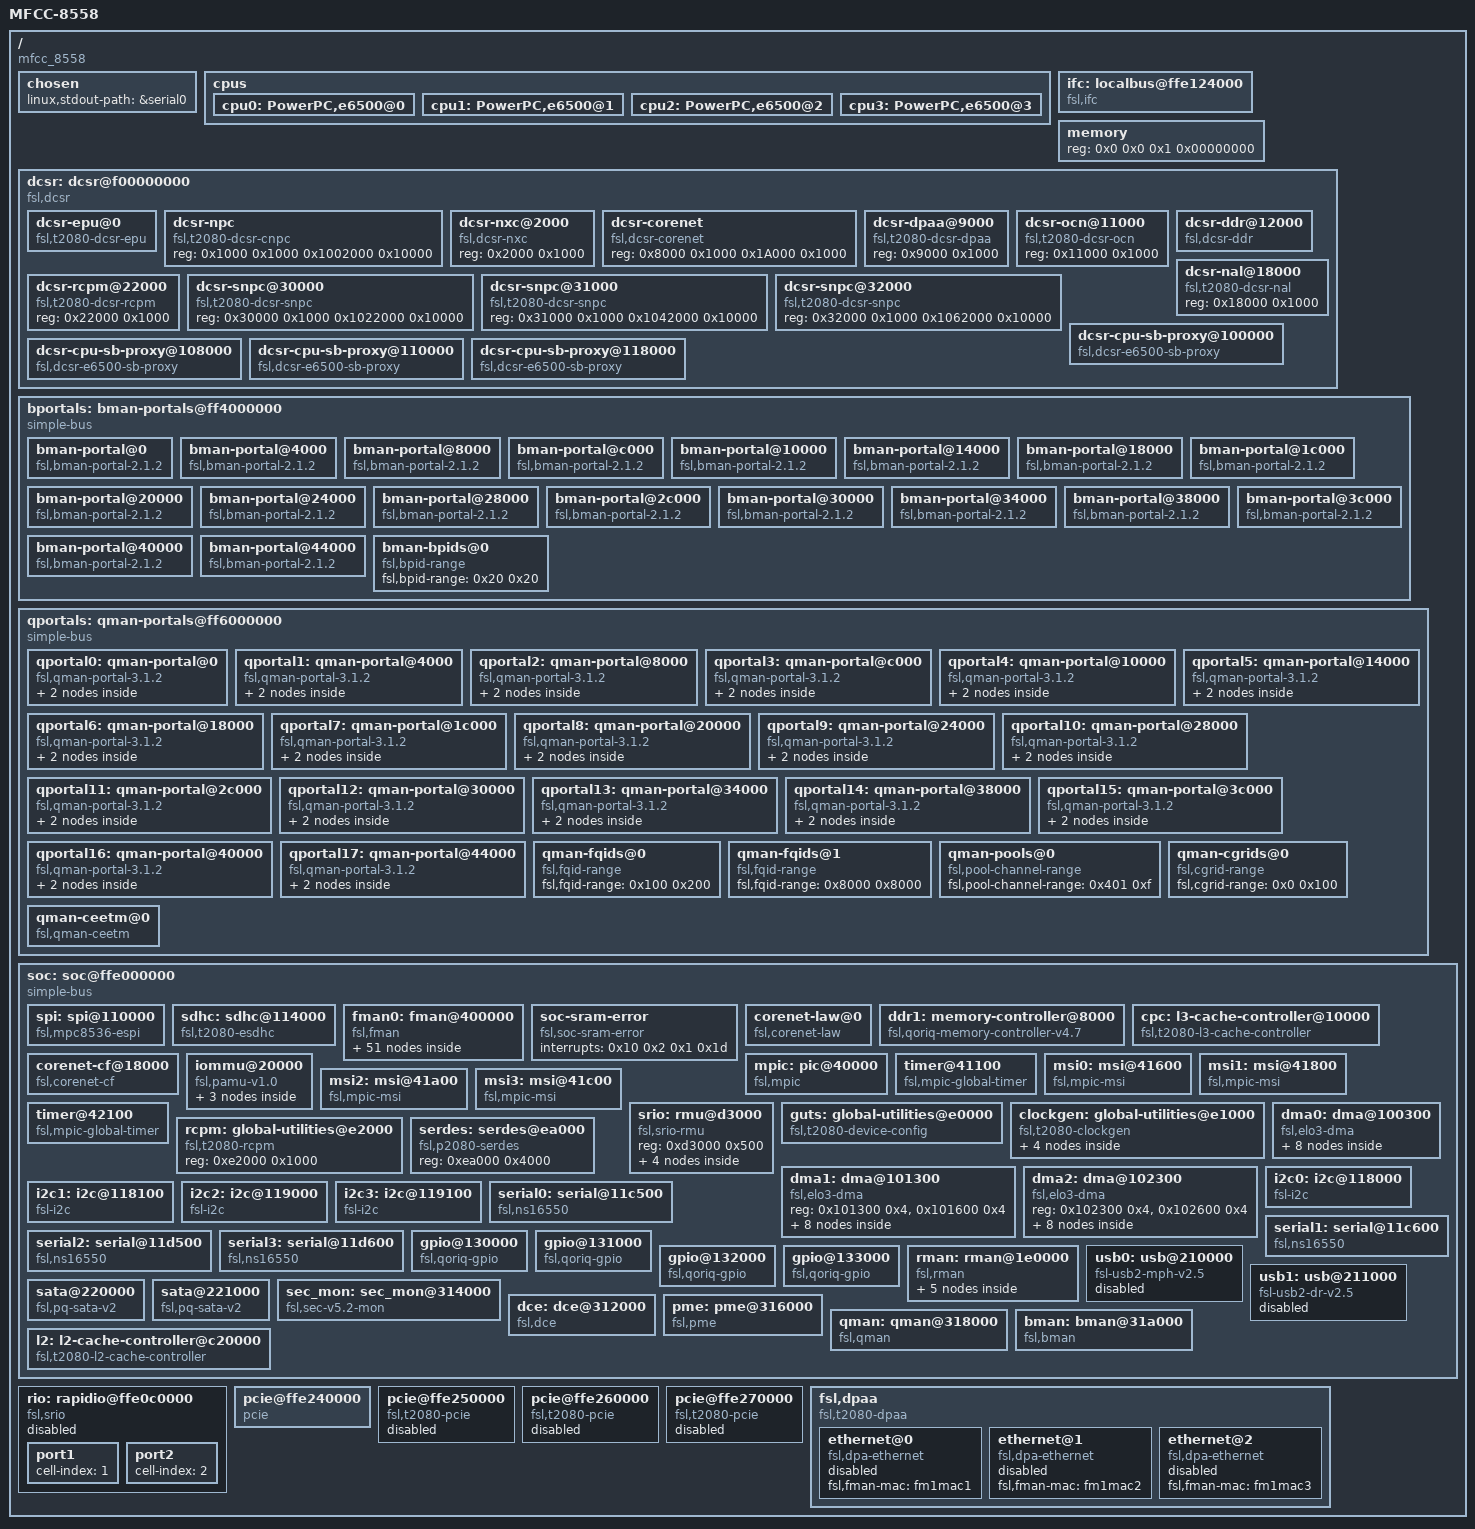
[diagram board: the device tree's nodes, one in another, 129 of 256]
/*
    Interrupts:
        <cell 1>:   interrupt number
        <cell 2>:   level-sense
                    - 0:    low-to-high edge triggered
                    - 1:    active low level-sense
                    - 2:    active high level-sense
                    - 3:    high-to-low edge triggered
        <cell 3>:   interrupt type
                    - 0:    external or normal SOC device interrupt
                    - 1:    error interrupt
        <cell 4>:   type specific cell
                    a) for error interrupts
                    - bit number of the error interrupt in error interrupt
                      summary register

*/

/* Reserve bootpage */
/memreserve/	0x00000000fffff000 0x0000000000001000;
/* Reserver memory for bman and qman */
/memreserve/	0x000000007c000000 0x0000000001000000;
/memreserve/	0x000000007e000000 0x0000000001000000;
/memreserve/	0x000000007d000000 0x0000000001000000;

/ {
	#address-cells = <2>;
	#size-cells = <2>;
	interrupt-parent = <&mpic>;
	model = "MFCC-8558";
	compatible = "mfcc_8558";

	chosen {
		linux,stdout-path = &serial0;
	};

	cpus {
		#address-cells = <1>;
		#size-cells = <0>;

		/*
		 * Temporarily add next-level-cache info in each cpu node so
		 * that uboot can do L2 cache fixup. This can be removed once
		 * u-boot can create cpu node with cache info.
		 */
		cpu0: PowerPC,e6500@0 {
			device_type = "cpu";
			reg = <0 1>;
			clocks = <&mux0>;
			next-level-cache = <&l2>;

			i-cache-sets = <0x40>;
			i-cache-size = <0x8000>;
			i-cache-block-size = <0x40>;
			cache-stash-id = <0x20>;
			d-cache-sets = <0x40>;
			d-cache-size = <0x8000>;
			d-cache-block-size = <0x40>;
		};
		cpu1: PowerPC,e6500@1 {
			device_type = "cpu";
			reg = <2 3>;
			clocks = <&mux0>;
			next-level-cache = <&l2>;

			i-cache-sets = <0x40>;
			i-cache-size = <0x8000>;
			i-cache-block-size = <0x40>;
			cache-stash-id = <0x24>;
			d-cache-sets = <0x40>;
			d-cache-size = <0x8000>;
			d-cache-block-size = <0x40>;
		};
		cpu2: PowerPC,e6500@2 {
			device_type = "cpu";
			reg = <4 5>;
			clocks = <&mux0>;
			next-level-cache = <&l2>;

			i-cache-sets = <0x40>;
			i-cache-size = <0x8000>;
			i-cache-block-size = <0x40>;
			cache-stash-id = <0x28>;
			d-cache-sets = <0x40>;
			d-cache-size = <0x8000>;
			d-cache-block-size = <0x40>;
		};
		cpu3: PowerPC,e6500@3 {
			device_type = "cpu";
			reg = <6 7>;
			clocks = <&mux0>;
			next-level-cache = <&l2>;

			i-cache-sets = <0x40>;
			i-cache-size = <0x8000>;
			i-cache-block-size = <0x40>;
			cache-stash-id = <0x2c>;
			d-cache-sets = <0x40>;
			d-cache-size = <0x8000>;
			d-cache-block-size = <0x40>;
		};
	};

	ifc: localbus@ffe124000 {
		compatible = "fsl,ifc", "simple-bus";

		reg = <15 0xfe124000 0 0x2000>;

		interrupts = <25 2 0 0>;
		#address-cells = <2>;
		#size-cells = <1>;
	};

	memory {
		device_type = "memory";
		reg = <0x0 0x0 0x1 0x00000000>;
	};

	dcsr: dcsr@f00000000 {
		ranges = <0x0 0xf 0x0 0x1072000>;
		#address-cells = <1>;
		#size-cells = <1>;
		compatible = "fsl,dcsr", "simple-bus";

		dcsr-epu@0 {
			compatible = "fsl,t2080-dcsr-epu", "fsl,dcsr-epu";
			interrupts = <52 2 0 0
			              84 2 0 0
			              85 2 0 0
			              94 2 0 0
			              95 2 0 0>;
			reg = <0x0 0x1000>;
		};
		dcsr-npc {
			compatible = "fsl,t2080-dcsr-cnpc", "fsl,dcsr-cnpc";
			reg = <0x1000 0x1000 0x1002000 0x10000>;
		};
		dcsr-nxc@2000 {
			compatible = "fsl,dcsr-nxc";
			reg = <0x2000 0x1000>;
		};
		dcsr-corenet {
			compatible = "fsl,dcsr-corenet";
			reg = <0x8000 0x1000 0x1A000 0x1000>;
		};
		dcsr-dpaa@9000 {
			compatible = "fsl,t2080-dcsr-dpaa", "fsl,dcsr-dpaa";
			reg = <0x9000 0x1000>;
		};
		dcsr-ocn@11000 {
			compatible = "fsl,t2080-dcsr-ocn", "fsl,dcsr-ocn";
			reg = <0x11000 0x1000>;
		};
		dcsr-ddr@12000 {
			compatible = "fsl,dcsr-ddr";
			dev-handle = <&ddr1>;
			reg = <0x12000 0x1000>;
		};
		dcsr-nal@18000 {
			compatible = "fsl,t2080-dcsr-nal", "fsl,dcsr-nal";
			reg = <0x18000 0x1000>;
		};
		dcsr-rcpm@22000 {
			compatible = "fsl,t2080-dcsr-rcpm", "fsl,dcsr-rcpm";
			reg = <0x22000 0x1000>;
		};
		dcsr-snpc@30000 {
			compatible = "fsl,t2080-dcsr-snpc", "fsl,dcsr-snpc";
			reg = <0x30000 0x1000 0x1022000 0x10000>;
		};
		dcsr-snpc@31000 {
			compatible = "fsl,t2080-dcsr-snpc", "fsl,dcsr-snpc";
			reg = <0x31000 0x1000 0x1042000 0x10000>;
		};
		dcsr-snpc@32000 {
			compatible = "fsl,t2080-dcsr-snpc", "fsl,dcsr-snpc";
			reg = <0x32000 0x1000 0x1062000 0x10000>;
		};
		dcsr-cpu-sb-proxy@100000 {
			compatible = "fsl,dcsr-e6500-sb-proxy", "fsl,dcsr-cpu-sb-proxy";
			cpu-handle = <&cpu0>;
			reg = <0x100000 0x1000 0x101000 0x1000>;
		};
		dcsr-cpu-sb-proxy@108000 {
			compatible = "fsl,dcsr-e6500-sb-proxy", "fsl,dcsr-cpu-sb-proxy";
			cpu-handle = <&cpu1>;
			reg = <0x108000 0x1000 0x109000 0x1000>;
		};
		dcsr-cpu-sb-proxy@110000 {
			compatible = "fsl,dcsr-e6500-sb-proxy", "fsl,dcsr-cpu-sb-proxy";
			cpu-handle = <&cpu2>;
			reg = <0x110000 0x1000 0x111000 0x1000>;
		};
		dcsr-cpu-sb-proxy@118000 {
			compatible = "fsl,dcsr-e6500-sb-proxy", "fsl,dcsr-cpu-sb-proxy";
			cpu-handle = <&cpu3>;
			reg = <0x118000 0x1000 0x119000 0x1000>;
		};
	};

	bportals: bman-portals@ff4000000 {
		ranges = <0x0 0xf 0xf4000000 0x2000000>;
		#address-cells = <0x1>;
		#size-cells = <0x1>;
		compatible = "simple-bus";

		bman-portal@0 {
			cell-index = <0x0>;
			compatible = "fsl,bman-portal-2.1.2", "fsl,bman-portal";
			reg = <0x0 0x4000 0x1000000 0x1000>;
			interrupts = <0x69 0x2 0x0 0x0>;
		};

		bman-portal@4000 {
			cell-index = <0x1>;
			compatible = "fsl,bman-portal-2.1.2", "fsl,bman-portal";
			reg = <0x4000 0x4000 0x1001000 0x1000>;
			interrupts = <0x6b 0x2 0x0 0x0>;
		};

		bman-portal@8000 {
			cell-index = <0x2>;
			compatible = "fsl,bman-portal-2.1.2", "fsl,bman-portal";
			reg = <0x8000 0x4000 0x1002000 0x1000>;
			interrupts = <0x6d 0x2 0x0 0x0>;
		};

		bman-portal@c000 {
			cell-index = <0x3>;
			compatible = "fsl,bman-portal-2.1.2", "fsl,bman-portal";
			reg = <0xc000 0x4000 0x1003000 0x1000>;
			interrupts = <0x6f 0x2 0x0 0x0>;
		};

		bman-portal@10000 {
			cell-index = <0x4>;
			compatible = "fsl,bman-portal-2.1.2", "fsl,bman-portal";
			reg = <0x10000 0x4000 0x1004000 0x1000>;
			interrupts = <0x71 0x2 0x0 0x0>;
		};

		bman-portal@14000 {
			cell-index = <0x5>;
			compatible = "fsl,bman-portal-2.1.2", "fsl,bman-portal";
			reg = <0x14000 0x4000 0x1005000 0x1000>;
			interrupts = <0x73 0x2 0x0 0x0>;
		};

		bman-portal@18000 {
			cell-index = <0x6>;
			compatible = "fsl,bman-portal-2.1.2", "fsl,bman-portal";
			reg = <0x18000 0x4000 0x1006000 0x1000>;
			interrupts = <0x75 0x2 0x0 0x0>;
		};

		bman-portal@1c000 {
			cell-index = <0x7>;
			compatible = "fsl,bman-portal-2.1.2", "fsl,bman-portal";
			reg = <0x1c000 0x4000 0x1007000 0x1000>;
			interrupts = <0x77 0x2 0x0 0x0>;
		};

		bman-portal@20000 {
			cell-index = <0x8>;
			compatible = "fsl,bman-portal-2.1.2", "fsl,bman-portal";
			reg = <0x20000 0x4000 0x1008000 0x1000>;
			interrupts = <0x79 0x2 0x0 0x0>;
		};

		bman-portal@24000 {
			cell-index = <0x9>;
			compatible = "fsl,bman-portal-2.1.2", "fsl,bman-portal";
			reg = <0x24000 0x4000 0x1009000 0x1000>;
			interrupts = <0x7b 0x2 0x0 0x0>;
		};

		bman-portal@28000 {
			cell-index = <0xa>;
			compatible = "fsl,bman-portal-2.1.2", "fsl,bman-portal";
			reg = <0x28000 0x4000 0x100a000 0x1000>;
			interrupts = <0x7d 0x2 0x0 0x0>;
		};

		bman-portal@2c000 {
			cell-index = <0xb>;
			compatible = "fsl,bman-portal-2.1.2", "fsl,bman-portal";
			reg = <0x2c000 0x4000 0x100b000 0x1000>;
			interrupts = <0x7f 0x2 0x0 0x0>;
		};

		bman-portal@30000 {
			cell-index = <0xc>;
			compatible = "fsl,bman-portal-2.1.2", "fsl,bman-portal";
			reg = <0x30000 0x4000 0x100c000 0x1000>;
			interrupts = <0x81 0x2 0x0 0x0>;
		};

		bman-portal@34000 {
			cell-index = <0xd>;
			compatible = "fsl,bman-portal-2.1.2", "fsl,bman-portal";
			reg = <0x34000 0x4000 0x100d000 0x1000>;
			interrupts = <0x83 0x2 0x0 0x0>;
		};

		bman-portal@38000 {
			cell-index = <0xe>;
			compatible = "fsl,bman-portal-2.1.2", "fsl,bman-portal";
			reg = <0x38000 0x4000 0x100e000 0x1000>;
			interrupts = <0x85 0x2 0x0 0x0>;
		};

		bman-portal@3c000 {
			cell-index = <0xf>;
			compatible = "fsl,bman-portal-2.1.2", "fsl,bman-portal";
			reg = <0x3c000 0x4000 0x100f000 0x1000>;
			interrupts = <0x87 0x2 0x0 0x0>;
		};

		bman-portal@40000 {
			cell-index = <0x10>;
			compatible = "fsl,bman-portal-2.1.2", "fsl,bman-portal";
			reg = <0x40000 0x4000 0x1010000 0x1000>;
			interrupts = <0x89 0x2 0x0 0x0>;
		};

		bman-portal@44000 {
			cell-index = <0x11>;
			compatible = "fsl,bman-portal-2.1.2", "fsl,bman-portal";
			reg = <0x44000 0x4000 0x1011000 0x1000>;
			interrupts = <0x8b 0x2 0x0 0x0>;
		};

		bman-bpids@0 {
			compatible = "fsl,bpid-range";
			fsl,bpid-range = <0x20 0x20>;
		};
	};

	qportals: qman-portals@ff6000000 {
		ranges = <0x0 0xf 0xf6000000 0x2000000>;
		#address-cells = <0x1>;
		#size-cells = <0x1>;
		compatible = "simple-bus";

		qportal0: qman-portal@0 {
			cell-index = <0x0>;
			compatible = "fsl,qman-portal-3.1.2", "fsl,qman-portal";
			reg = <0x0 0x4000 0x1000000 0x1000>;
			interrupts = <0x68 0x2 0x0 0x0>;
			fsl,qman-channel-id = <0x0>;

			fman@0 {
				dev-handle = <&fman0>;
			};

			pme@0 {
				dev-handle = <&pme>;
			};
		};

		qportal1: qman-portal@4000 {
			cell-index = <0x1>;
			compatible = "fsl,qman-portal-3.1.2", "fsl,qman-portal";
			reg = <0x4000 0x4000 0x1001000 0x1000>;
			interrupts = <0x6a 0x2 0x0 0x0>;
			fsl,qman-channel-id = <0x1>;

			fman@0 {
				dev-handle = <&fman0>;
			};

			pme@0 {
				dev-handle = <&pme>;
			};
		};

		qportal2: qman-portal@8000 {
			cell-index = <0x2>;
			compatible = "fsl,qman-portal-3.1.2", "fsl,qman-portal";
			reg = <0x8000 0x4000 0x1002000 0x1000>;
			interrupts = <0x6c 0x2 0x0 0x0>;
			fsl,qman-channel-id = <0x2>;

			fman@0 {
				dev-handle = <&fman0>;
			};

			pme@0 {
				dev-handle = <&pme>;
			};
		};

		qportal3: qman-portal@c000 {
			cell-index = <0x3>;
			compatible = "fsl,qman-portal-3.1.2", "fsl,qman-portal";
			reg = <0xc000 0x4000 0x1003000 0x1000>;
			interrupts = <0x6e 0x2 0x0 0x0>;
			fsl,qman-channel-id = <0x3>;

			fman@0 {
				dev-handle = <&fman0>;
			};

			pme@0 {
				dev-handle = <&pme>;
			};
		};

		qportal4: qman-portal@10000 {
			cell-index = <0x4>;
			compatible = "fsl,qman-portal-3.1.2", "fsl,qman-portal";
			reg = <0x10000 0x4000 0x1004000 0x1000>;
			interrupts = <0x70 0x2 0x0 0x0>;
			fsl,qman-channel-id = <0x4>;

			fman@0 {
				dev-handle = <&fman0>;
			};

			pme@0 {
				dev-handle = <&pme>;
			};
		};

		qportal5: qman-portal@14000 {
			cell-index = <0x5>;
			compatible = "fsl,qman-portal-3.1.2", "fsl,qman-portal";
			reg = <0x14000 0x4000 0x1005000 0x1000>;
			interrupts = <0x72 0x2 0x0 0x0>;
			fsl,qman-channel-id = <0x5>;

			fman@0 {
				dev-handle = <&fman0>;
			};

			pme@0 {
				dev-handle = <&pme>;
			};
		};

		qportal6: qman-portal@18000 {
			cell-index = <0x6>;
			compatible = "fsl,qman-portal-3.1.2", "fsl,qman-portal";
			reg = <0x18000 0x4000 0x1006000 0x1000>;
			interrupts = <0x74 0x2 0x0 0x0>;
			fsl,qman-channel-id = <0x6>;

			fman@0 {
				dev-handle = <&fman0>;
			};

			pme@0 {
				dev-handle = <&pme>;
			};
		};

		qportal7: qman-portal@1c000 {
			cell-index = <0x7>;
			compatible = "fsl,qman-portal-3.1.2", "fsl,qman-portal";
			reg = <0x1c000 0x4000 0x1007000 0x1000>;
			interrupts = <0x76 0x2 0x0 0x0>;
			fsl,qman-channel-id = <0x7>;

			fman@0 {
				dev-handle = <&fman0>;
			};

			pme@0 {
				dev-handle = <&pme>;
			};
		};

		qportal8: qman-portal@20000 {
			cell-index = <0x8>;
			compatible = "fsl,qman-portal-3.1.2", "fsl,qman-portal";
			reg = <0x20000 0x4000 0x1008000 0x1000>;
			interrupts = <0x78 0x2 0x0 0x0>;
			fsl,qman-channel-id = <0x8>;

			fman@0 {
				dev-handle = <&fman0>;
			};

			pme@0 {
				dev-handle = <&pme>;
			};
		};

		qportal9: qman-portal@24000 {
			cell-index = <0x9>;
			compatible = "fsl,qman-portal-3.1.2", "fsl,qman-portal";
			reg = <0x24000 0x4000 0x1009000 0x1000>;
			interrupts = <0x7a 0x2 0x0 0x0>;
			fsl,qman-channel-id = <0x9>;

			fman@0 {
				dev-handle = <&fman0>;
			};

			pme@0 {
				dev-handle = <&pme>;
			};
		};

		qportal10: qman-portal@28000 {
			cell-index = <0xa>;
			compatible = "fsl,qman-portal-3.1.2", "fsl,qman-portal";
			reg = <0x28000 0x4000 0x100a000 0x1000>;
			interrupts = <0x7c 0x2 0x0 0x0>;
			fsl,qman-channel-id = <0xa>;

			fman@0 {
				dev-handle = <&fman0>;
			};

			pme@0 {
				dev-handle = <&pme>;
			};
		};

		qportal11: qman-portal@2c000 {
			cell-index = <0xb>;
			compatible = "fsl,qman-portal-3.1.2", "fsl,qman-portal";
			reg = <0x2c000 0x4000 0x100b000 0x1000>;
			interrupts = <0x7e 0x2 0x0 0x0>;
			fsl,qman-channel-id = <0xb>;

			fman@0 {
				dev-handle = <&fman0>;
			};

			pme@0 {
				dev-handle = <&pme>;
			};
		};

		qportal12: qman-portal@30000 {
			cell-index = <0xc>;
			compatible = "fsl,qman-portal-3.1.2", "fsl,qman-portal";
			reg = <0x30000 0x4000 0x100c000 0x1000>;
			interrupts = <0x80 0x2 0x0 0x0>;
			fsl,qman-channel-id = <0xc>;

			fman@0 {
				dev-handle = <&fman0>;
			};

			pme@0 {
				dev-handle = <&pme>;
			};
		};

		qportal13: qman-portal@34000 {
			cell-index = <0xd>;
			compatible = "fsl,qman-portal-3.1.2", "fsl,qman-portal";
			reg = <0x34000 0x4000 0x100d000 0x1000>;
			interrupts = <0x82 0x2 0x0 0x0>;
			fsl,qman-channel-id = <0xd>;

			fman@0 {
				dev-handle = <&fman0>;
			};

			pme@0 {
				dev-handle = <&pme>;
			};
		};

		qportal14: qman-portal@38000 {
			cell-index = <0xe>;
			compatible = "fsl,qman-portal-3.1.2", "fsl,qman-portal";
			reg = <0x38000 0x4000 0x100e000 0x1000>;
			interrupts = <0x84 0x2 0x0 0x0>;
			fsl,qman-channel-id = <0xe>;

			fman@0 {
				dev-handle = <&fman0>;
			};

			pme@0 {
				dev-handle = <&pme>;
			};
		};

		qportal15: qman-portal@3c000 {
			cell-index = <0xf>;
			compatible = "fsl,qman-portal-3.1.2", "fsl,qman-portal";
			reg = <0x3c000 0x4000 0x100f000 0x1000>;
			interrupts = <0x86 0x2 0x0 0x0>;
			fsl,qman-channel-id = <0xf>;

			fman@0 {
				dev-handle = <&fman0>;
			};

			pme@0 {
				dev-handle = <&pme>;
			};
		};

		qportal16: qman-portal@40000 {
			cell-index = <0x10>;
			compatible = "fsl,qman-portal-3.1.2", "fsl,qman-portal";
			reg = <0x40000 0x4000 0x1010000 0x1000>;
			interrupts = <0x88 0x2 0x0 0x0>;
			fsl,qman-channel-id = <0x10>;

			fman@0 {
				dev-handle = <&fman0>;
			};

			pme@0 {
				dev-handle = <&pme>;
			};
		};

		qportal17: qman-portal@44000 {
			cell-index = <0x11>;
			compatible = "fsl,qman-portal-3.1.2", "fsl,qman-portal";
			reg = <0x44000 0x4000 0x1011000 0x1000>;
			interrupts = <0x8a 0x2 0x0 0x0>;
			fsl,qman-channel-id = <0x11>;

			fman@0 {
				dev-handle = <&fman0>;
			};

			pme@0 {
				dev-handle = <&pme>;
			};
		};

		qman-fqids@0 {
			compatible = "fsl,fqid-range";
			fsl,fqid-range = <0x100 0x200>;
		};

		qman-fqids@1 {
			compatible = "fsl,fqid-range";
			fsl,fqid-range = <0x8000 0x8000>;
		};

		qman-pools@0 {
			compatible = "fsl,pool-channel-range";
			fsl,pool-channel-range = <0x401 0xf>;
		};

		qman-cgrids@0 {
			compatible = "fsl,cgrid-range";
			fsl,cgrid-range = <0x0 0x100>;
		};

		qman-ceetm@0 {
			compatible = "fsl,qman-ceetm";
			fsl,ceetm-lfqid-range = <0xf00000 0x1000>;
			fsl,ceetm-sp-range = <0x0 0xc>;
			fsl,ceetm-lni-range = <0x0 0x8>;
			fsl,ceetm-channel-range = <0x0 0x20>;
		};
	};

	soc: soc@ffe000000 {
		bus-frequency = <600000000>;
		ranges = <0x0 0xf 0xfe000000 0x1000000>;
		reg = <0xf 0xfe000000 0x0 0x1000>;
		#address-cells = <0x1>;
		#size-cells = <0x1>;
		device_type = "soc";
		compatible = "simple-bus";

		spi: spi@110000 {
			#address-cells = <0x1>;
			#size-cells = <0x0>;
			compatible = "fsl,mpc8536-espi";
			reg = <0x110000 0x1000>;
			interrupts = <53 2 0 0>;
			fsl,espi-num-chipselects = <0x4>;
		};

		sdhc: sdhc@114000 {
			compatible = "fsl,t2080-esdhc", "fsl,esdhc";
			reg = <0x114000 0x1000>;
			voltage-ranges = <1800 1800 3300 3300>;
			interrupts = <48 2 0 0>;
			fsl,iommu-parent = <&pamu1>;
			clock-frequency = <350000000>;
			sdhci,auto-cmd12;
		};

		fman0: fman@400000 {
			#address-cells = <0x1>;
			#size-cells = <0x1>;
			cell-index = <0x0>;
			compatible = "fsl,fman", "simple-bus";
			ranges = <0x0 0x400000 0x100000>;
			reg = <0x400000 0x100000>;
			clock-frequency = <1200000000>;
			interrupts = <96 2 0 0
			              16 2 1 1>;

			fm1mac1: ethernet@e0000 {
				compatible = "fsl,fman-memac";
				phy-connection-type = "sgmii";
				cell-index = <0x0>;
				reg = <0xe0000 0x1000>;
				fsl,port-handles = <&fman0_rx0 &fman0_tx0>;
				ptimer-handle = <&ptp_timer0>;
				status = "disabled";
			};

			fm1mac2: ethernet@e2000 {
				compatible = "fsl,fman-memac";
				phy-connection-type = "sgmii";
				cell-index = <0x1>;
				reg = <0xe2000 0x1000>;
				fsl,port-handles = <&fman0_rx1 &fman0_tx1>;
				ptimer-handle = <&ptp_timer0>;
				status = "disabled";
			};

			fm1mac3: ethernet@e4000 {
				compatible = "fsl,fman-memac";
				phy-connection-type = "sgmii";
				cell-index = <0x2>;
				reg = <0xe4000 0x1000>;
				fsl,port-handles = <&fman0_rx2 &fman0_tx2>;
				ptimer-handle = <&ptp_timer0>;
				status = "disabled";
			};

			fm1mac4: ethernet@e6000 {
				compatible = "fsl,fman-memac";
				cell-index = <0x3>;
				reg = <0xe6000 0x1000>;
				fsl,port-handles = <&fman0_rx3 &fman0_tx3>;
				ptimer-handle = <&ptp_timer0>;
				status = "disabled";
			};

			fm1mac5: ethernet@e8000 {
				compatible = "fsl,fman-memac";
				cell-index = <0x4>;
				reg = <0xe8000 0x1000>;
				fsl,port-handles = <&fman0_rx4 &fman0_tx4>;
				ptimer-handle = <&ptp_timer0>;
				status = "disabled";
			};

			fm1mac6: ethernet@ea000 {
				compatible = "fsl,fman-memac";
				cell-index = <0x5>;
				reg = <0xea000 0x1000>;
				fsl,port-handles = <&fman0_rx5 &fman0_tx5>;
				ptimer-handle = <&ptp_timer0>;
				status = "disabled";
			};

			fm1mac9: ethernet@f0000 {
				compatible = "fsl,fman-memac";
				phy-connection-type = "xgmii";
				cell-index = <8>;
				reg = <0xf0000 0x1000>;
				fsl,port-handles = <&fman0_10g_rx0 &fman0_10g_tx0>;
				status = "disabled";
			};

			fm1mac10: ethernet@f2000 {
				compatible = "fsl,fman-memac";
				cell-index = <9>;
				reg = <0xf2000 0x1000>;
				fsl,port-handles = <&fman0_10g_rx1 &fman0_10g_tx1>;
				status = "disabled";
			};

			mdio@fc000 {
				#address-cells = <1>;
				#size-cells = <0>;
				compatible = "fsl,fman-memac-mdio";
				reg = <0xfc000 0x1000>;
				interrupts = <0x64 0x1 0x0 0x0>;
				status = "disabled";
			};

			mdio@fd000 {
				#address-cells = <1>;
				#size-cells = <0>;
				compatible = "fsl,fman-memac-mdio";
				reg = <0xfd000 0x1000>;
				interrupts = <0x65 0x1 0x0 0x0>;
				status = "disabled";
			};

			cc {
				compatible = "fsl,fman-cc";
			};

			muram@0 {
				compatible = "fsl,fman-muram";
				reg = <0x0 0x60000>;
			};

			bmi@80000 {
				compatible = "fsl,fman-bmi";
				reg = <0x80000 0x400>;
			};

			qmi@80400 {
				compatible = "fsl,fman-qmi";
				reg = <0x80400 0x400>;
			};

			fman0_oh1: port@82000 {
				cell-index = <0>;
				compatible = "fsl,fman-port-oh";
				reg = <0x82000 0x1000>;
				fsl,qman-channel-id = <0x809>;
			};

			fman_oh2: port@83000 {
				cell-index = <1>;
				compatible = "fsl,fman-port-oh";
				reg = <0x83000 0x1000>;
				fsl,qman-channel-id = <0x80a>;
			};

			fman_oh3: port@84000 {
				cell-index = <2>;
				compatible = "fsl,fman-port-oh";
				reg = <0x84000 0x1000>;
				fsl,qman-channel-id = <0x80b>;
			};

			fman_oh4: port@85000 {
				cell-index = <3>;
				compatible = "fsl,fman-port-oh";
				reg = <0x85000 0x1000>;
				fsl,qman-channel-id = <0x80c>;
			};

			fman_oh5: port@86000 {
				cell-index = <4>;
				compatible = "fsl,fman-port-oh";
				reg = <0x86000 0x1000>;
				fsl,qman-channel-id = <0x80d>;
			};

			fman_oh6: port@87000 {
				cell-index = <5>;
				compatible = "fsl,fman-port-oh";
				reg = <0x87000 0x1000>;
				fsl,qman-channel-id = <0x80e>;
			};

			policer@c0000 {
				compatible = "fsl,fman-policer";
				reg = <0xc0000 0x1000>;
			};

			keygen@c1000 {
				compatible = "fsl,fman-keygen";
				reg = <0xc1000 0x1000>;
			};

			dma@c2000 {
				compatible = "fsl,fman-dma";
				reg = <0xc2000 0x1000>;
			};

			fpm@c3000 {
				compatible = "fsl,fman-fpm";
				reg = <0xc3000 0x1000>;
			};

			parser@c7000 {
				compatible = "fsl,fman-parser";
				reg = <0xc7000 0x1000>;
			};

			vsps@dc000 {
				compatible = "fsl,fman-vsps";
				reg = <0xdc000 0x1000>;
			};

			ptp_timer0: rtc@fe000 {
				compatible = "fsl,fman-rtc";
				reg = <0xfe000 0x1000>;
			};

			fman0_rx0: port@88000 {
				cell-index = <0>;
				compatible = "fsl,fman-port-1g-rx";
				reg = <0x88000 0x1000>;
			};

			fman0_tx0: port@a8000 {
				cell-index = <0>;
				compatible = "fsl,fman-port-1g-tx";
				reg = <0xa8000 0x1000>;
				fsl,qman-channel-id = <0x802>;
			};

			mdio@e1000 {
				#address-cells = <1>;
				#size-cells = <0>;
				compatible = "fsl,fman-memac-mdio";
				reg = <0xe1000 0x1000>;
				status = "disabled";
			};

			fman0_rx1: port@89000 {
				cell-index = <1>;
				compatible = "fsl,fman-port-1g-rx";
				reg = <0x89000 0x1000>;
			};

			fman0_tx1: port@a9000 {
				cell-index = <1>;
				compatible = "fsl,fman-port-1g-tx";
				reg = <0xa9000 0x1000>;
				fsl,qman-channel-id = <0x803>;
			};

			mdio@e3000 {
				#address-cells = <1>;
				#size-cells = <0>;
				compatible = "fsl,fman-memac-mdio";
				reg = <0xe3000 0x1000>;
				status = "disabled";
			};

			fman0_rx2: port@8a000 {
				cell-index = <2>;
				compatible = "fsl,fman-port-1g-rx";
				reg = <0x8a000 0x1000>;
			};

			fman0_tx2: port@aa000 {
				cell-index = <2>;
				compatible = "fsl,fman-port-1g-tx";
				reg = <0xaa000 0x1000>;
				fsl,qman-channel-id = <0x804>;
			};

			mdio@e5000 {
				#address-cells = <1>;
				#size-cells = <0>;
				compatible = "fsl,fman-memac-mdio";
				reg = <0xe5000 0x1000>;
				status = "disabled";
			};

			fman0_rx3: port@8b000 {
				cell-index = <3>;
				compatible = "fsl,fman-port-1g-rx";
				reg = <0x8b000 0x1000>;
			};

			fman0_tx3: port@ab000 {
				cell-index = <3>;
				compatible = "fsl,fman-port-1g-tx";
				reg = <0xab000 0x1000>;
				fsl,qman-channel-id = <0x805>;
			};

			mdio@e7000 {
				#address-cells = <0x1>;
				#size-cells = <0x0>;
				compatible = "fsl,fman-memac-mdio";
				reg = <0xe7000 0x1000>;
				status = "disabled";
			};

			fman0_rx4: port@8c000 {
				cell-index = <4>;
				compatible = "fsl,fman-port-1g-rx";
				reg = <0x8c000 0x1000>;
			};

			fman0_tx4: port@ac000 {
				cell-index = <4>;
				compatible = "fsl,fman-port-1g-tx";
				reg = <0xac000 0x1000>;
				fsl,qman-channel-id = <0x806>;
			};

			mdio@e9000 {
				#address-cells = <0x1>;
				#size-cells = <0x0>;
				compatible = "fsl,fman-memac-mdio";
				reg = <0xe9000 0x1000>;
				status = "disabled";
			};

			fman0_rx5: port@8d000 {
				cell-index = <5>;
				compatible = "fsl,fman-port-1g-rx";
				reg = <0x8d000 0x1000>;
			};

			fman0_tx5: port@ad000 {
				cell-index = <5>;
				compatible = "fsl,fman-port-1g-tx";
				reg = <0xad000 0x1000>;
				fsl,qman-channel-id = <0x807>;
			};

			mdio@eb000 {
				#address-cells = <1>;
				#size-cells = <0>;
				compatible = "fsl,fman-memac-mdio";
				reg = <0xeb000 0x1000>;
				status = "disabled";
			};

			fman0_10g_rx0: port@90000 {
				cell-index = <0>;
				compatible = "fsl,fman-port-10g-rx";
				reg = <0x90000 0x1000>;
			};

			fman0_10g_rx1: port@91000 {
				cell-index = <1>;
				compatible = "fsl,fman-port-10g-rx";
				reg = <0x91000 0x1000>;
			};

			fman0_10g_tx0: port@b0000 {
				cell-index = <0>;
				compatible = "fsl,fman-port-10g-tx";
				reg = <0xb0000 0x1000>;
				fsl,qman-channel-id = <0x800>;
			};

			fman0_10g_tx1: port@b1000 {
				cell-index = <1>;
				compatible = "fsl,fman-port-10g-tx";
				reg = <0xb1000 0x1000>;
				fsl,qman-channel-id = <0x800>;
			};

			mdio@f1000 {
				#address-cells = <1>;
				#size-cells = <0>;
				compatible = "fsl,fman-memac-mdio";
				reg = <0xf1000 0x1000>;
				status = "disabled";
			};

			mdio@f3000 {
				#address-cells = <1>;
				#size-cells = <0>;
				compatible = "fsl,fman-memac-mdio";
				reg = <0xf3000 0x1000>;
				status = "disabled";
			};
		};

		soc-sram-error {
				compatible = "fsl,soc-sram-error";
				interrupts = <0x10 0x2 0x1 0x1d>;
		};

		corenet-law@0 {
				compatible = "fsl,corenet-law";
				reg = <0x0 0x1000>;
				fsl,num-laws = <0x20>;
		};

		ddr1: memory-controller@8000 {
			compatible = "fsl,qoriq-memory-controller-v4.7", "fsl,qoriq-memory-controller";
			reg = <0x8000 0x1000>;
			interrupts = <0x10 0x2 0x1 0x17>;
		};

		cpc: l3-cache-controller@10000 {
			compatible = "fsl,t2080-l3-cache-controller", "cache";
			reg = <0x10000 0x1000
			       0x11000 0x1000
			       0x12000 0x1000>;
			interrupts = <16 2 1 27
			              16 2 1 26
			              16 2 1 25>;
		};

		corenet-cf@18000 {
			compatible = "fsl,corenet-cf";
			reg = <0x18000 0x1000>;
			interrupts = <16 2 1 31>;
			fsl,ccf-num-csdids = <32>;
			fsl,ccf-num-snoopids = <32>;
		};

		iommu@20000 {
			compatible = "fsl,pamu-v1.0", "fsl,pamu";
			reg = <0x20000 0x6000>;
			interrupts = <24 2 0 0
			              16 2 1 30>;
			#address-cells = <0x1>;
			#size-cells = <0x1>;
			ranges = <0x0 0x20000 0x4000>;

			pamu0: pamu@0 {
				reg = <0x00000000 0x00001000>;
				fsl,primary-cache-geometry = <0x00000020 0x00000001>;
				fsl,secondary-cache-geometry = <0x00000080 0x00000002>;
			};

			pamu1: pamu@1000 {
				reg = <0x00001000 0x00001000>;
				fsl,primary-cache-geometry = <0x00000020 0x00000001>;
				fsl,secondary-cache-geometry = <0x00000080 0x00000002>;
			};

			pamu2: pamu@2000 {
				reg = <0x00002000 0x00001000>;
				fsl,primary-cache-geometry = <0x00000020 0x00000001>;
				fsl,secondary-cache-geometry = <0x00000080 0x00000002>;
			};
		};

		mpic: pic@40000 {
			interrupt-controller;
			#address-cells = <0>;
			#interrupt-cells = <4>;
			reg = <0x40000 0x40000>;
			compatible = "fsl,mpic", "chrp,open-pic";
			device_type = "open-pic";
			clock-frequency = <0x0>;
		};

		timer@41100 {
			compatible = "fsl,mpic-global-timer";
			reg = <0x41100 0x100 0x41300 4>;
			interrupts = <0 0 3 0
			              1 0 3 0
			              2 0 3 0
			              3 0 3 0>;
		};

		msi0: msi@41600 {
			compatible = "fsl,mpic-msi";
			reg = <0x41600 0x200 0x44140 4>;
			msi-available-ranges = <0x0 0x100>;
			interrupts = <0xe0 0 0 0
			              0xe1 0 0 0
			              0xe2 0 0 0
			              0xe3 0 0 0
			              0xe4 0 0 0
			              0xe5 0 0 0
			              0xe6 0 0 0
			              0xe7 0 0 0>;
		};

		msi1: msi@41800 {
			compatible = "fsl,mpic-msi";
			reg = <0x41800 0x200 0x45140 4>;
			msi-available-ranges = <0x0 0x100>;
			interrupts = <0xe8 0 0 0
			              0xe9 0 0 0
			              0xea 0 0 0
			              0xeb 0 0 0
			              0xec 0 0 0
			              0xed 0 0 0
			              0xee 0 0 0
			              0xef 0 0 0>;
		};

		msi2: msi@41a00 {
			compatible = "fsl,mpic-msi";
			reg = <0x41a00 0x200 0x46140 4>;
			msi-available-ranges = <0x0 0x100>;
			interrupts = <0xf0 0 0 0
			              0xf1 0 0 0
			              0xf2 0 0 0
			              0xf3 0 0 0
			              0xf4 0 0 0
			              0xf5 0 0 0
			              0xf6 0 0 0
			              0xf7 0 0 0>;
		};

		msi3: msi@41c00 {
			compatible = "fsl,mpic-msi";
			reg = <0x41c00 0x200 0x47140 4>;
			msi-available-ranges = <0x0 0x100>;
			interrupts = <0xf8 0 0 0
			              0xf9 0 0 0
			              0xfa 0 0 0
			              0xfb 0 0 0
			              0xfc 0 0 0
			              0xfd 0 0 0
			              0xfe 0 0 0
			              0xff 0 0 0>;
		};

		timer@42100 {
			compatible = "fsl,mpic-global-timer";
			reg = <0x42100 0x100 0x42300 4>;
			interrupts = <4 0 3 0
			              5 0 3 0
			              6 0 3 0
			              7 0 3 0>;
		};

		srio: rmu@d3000 {
			#address-cells = <0x1>;
			#size-cells = <0x1>;
			compatible = "fsl,srio-rmu";
			reg = <0xd3000 0x500>;
			ranges = <0x0 0xd3000 0x500>;
			message-unit@0 {
				compatible = "fsl,srio-msg-unit";
				reg = <0x0 0x100>;
				interrupts = <0x3c 0x2 0x0 0x0
				              0x3d 0x2 0x0 0x0>;
			};
			message-unit@100 {
				compatible = "fsl,srio-msg-unit";
				reg = <0x100 0x100>;
				interrupts = <0x3e 0x2 0x0 0x0
				              0x3f 0x2 0x0 0x0>;
			};
			doorbell-unit@400 {
				compatible = "fsl,srio-dbell-unit";
				reg = <0x400 0x80>;
				interrupts = <0x38 0x2 0x0 0x0
				              0x39 0x2 0x0 0x0>;
			};
			port-write-unit@4e0 {
				compatible = "fsl,srio-port-write-unit";
				reg = <0x4e0 0x20>;
				interrupts = <0x10 0x2 0x1 0xb>;
			};
		};

		guts: global-utilities@e0000 {
			compatible = "fsl,t2080-device-config",
			             "fsl,qoriq-device-config-2.0";
			reg = <0xe0000 0xe00>;
			fsl,has-rstcr;
			fsl,liodn-bits = <12>;
		};

		clockgen: global-utilities@e1000 {
			compatible = "fsl,t2080-clockgen",
			             "fsl,qoriq-clockgen-2.0",
			             "fixed-clock";
			reg = <0xe1000 0x1000>;
			clock-output-names = "sysclk";
			#clock-cells = <0>;

			#address-cells = <1>;
			#size-cells = <0>;
			pll0: pll0@800 {
				#clock-cells = <1>;
				reg = <0x800>;
				compatible = "fsl,core-pll-clock";
				clocks = <&clockgen>;
				clock-output-names = "pll0", "pll0-div2", "pll0-div4";
			};
			pll1: pll1@820 {
				#clock-cells = <1>;
				reg = <0x820>;
				compatible = "fsl,core-pll-clock";
				clocks = <&clockgen>;
				clock-output-names = "pll1", "pll1-div2", "pll1-div4";
			};
			mux0: mux0@0 {
				#clock-cells = <0>;
				reg = <0x0>;
				compatible = "fsl,core-mux-clock";
				clocks = <&pll0 0>, <&pll0 1>, <&pll0 2>,
					 <&pll1 0>, <&pll1 1>, <&pll1 2>;
				clock-names = "pll0_0", "pll0_1", "pll0_2",
					      "pll1_0", "pll1_1", "pll1_2";
				clock-output-names = "cmux0";
			};
			mux1: mux1@20 {
				#clock-cells = <0>;
				reg = <0x20>;
				compatible = "fsl,core-mux-clock";
				clocks = <&pll0 0>, <&pll0 1>, <&pll0 2>,
					 <&pll1 0>, <&pll1 1>, <&pll1 2>;
				clock-names = "pll0_0", "pll0_1", "pll0_2",
					      "pll1_0", "pll1_1", "pll1_2";
				clock-output-names = "cmux1";
			};
		};

		rcpm: global-utilities@e2000 {
			compatible = "fsl,t2080-rcpm", "fsl,qoriq-rcpm-2.0";
			reg = <0xe2000 0x1000>;
		};

		serdes: serdes@ea000 {
			compatible = "fsl,p2080-serdes";
			reg = <0xea000 0x4000>;
		};

		dma0: dma@100300 {
			#address-cells = <1>;
			#size-cells = <1>;
			compatible = "fsl,elo3-dma";
			reg = <0x100300 0x4>,
			      <0x100600 0x4>;
			ranges = <0x0 0x100100 0x500>;
			fsl,iommu-parent = <&pamu0>;
			dma-channel@0 {
				compatible = "fsl,eloplus-dma-channel";
				reg = <0x0 0x80>;
				interrupts = <28 2 0 0>;
			};
			dma-channel@80 {
				compatible = "fsl,eloplus-dma-channel";
				reg = <0x80 0x80>;
				interrupts = <29 2 0 0>;
			};
			dma-channel@100 {
				compatible = "fsl,eloplus-dma-channel";
				reg = <0x100 0x80>;
				interrupts = <30 2 0 0>;
			};
			dma-channel@180 {
				compatible = "fsl,eloplus-dma-channel";
				reg = <0x180 0x80>;
				interrupts = <31 2 0 0>;
			};
			dma-channel@300 {
				compatible = "fsl,eloplus-dma-channel";
				reg = <0x300 0x80>;
				interrupts = <76 2 0 0>;
			};
			dma-channel@380 {
				compatible = "fsl,eloplus-dma-channel";
				reg = <0x380 0x80>;
				interrupts = <77 2 0 0>;
			};
			dma-channel@400 {
				compatible = "fsl,eloplus-dma-channel";
				reg = <0x400 0x80>;
				interrupts = <78 2 0 0>;
			};
			dma-channel@480 {
				compatible = "fsl,eloplus-dma-channel";
				reg = <0x480 0x80>;
				interrupts = <79 2 0 0>;
			};
		};

		dma1: dma@101300 {
			#address-cells = <1>;
			#size-cells = <1>;
			compatible = "fsl,elo3-dma";
			reg = <0x101300 0x4>,
			      <0x101600 0x4>;
			ranges = <0x0 0x101100 0x500>;
			dma-channel@0 {
				compatible = "fsl,eloplus-dma-channel";
				reg = <0x0 0x80>;
				interrupts = <32 2 0 0>;
			};
			dma-channel@80 {
				compatible = "fsl,eloplus-dma-channel";
				reg = <0x80 0x80>;
				interrupts = <33 2 0 0>;
			};
			dma-channel@100 {
				compatible = "fsl,eloplus-dma-channel";
				reg = <0x100 0x80>;
				interrupts = <34 2 0 0>;
			};
			dma-channel@180 {
				compatible = "fsl,eloplus-dma-channel";
				reg = <0x180 0x80>;
				interrupts = <35 2 0 0>;
			};
			dma-channel@300 {
				compatible = "fsl,eloplus-dma-channel";
				reg = <0x300 0x80>;
				interrupts = <80 2 0 0>;
			};
			dma-channel@380 {
				compatible = "fsl,eloplus-dma-channel";
				reg = <0x380 0x80>;
				interrupts = <81 2 0 0>;
			};
			dma-channel@400 {
				compatible = "fsl,eloplus-dma-channel";
				reg = <0x400 0x80>;
				interrupts = <82 2 0 0>;
			};
			dma-channel@480 {
				compatible = "fsl,eloplus-dma-channel";
				reg = <0x480 0x80>;
				interrupts = <83 2 0 0>;
			};
		};

		dma2: dma@102300 {
			#address-cells = <1>;
			#size-cells = <1>;
			compatible = "fsl,elo3-dma";
			reg = <0x102300 0x4>,
			      <0x102600 0x4>;
			ranges = <0x0 0x102100 0x500>;
			dma-channel@0 {
				compatible = "fsl,eloplus-dma-channel";
				reg = <0x0 0x80>;
				interrupts = <464 2 0 0>;
			};
			dma-channel@80 {
				compatible = "fsl,eloplus-dma-channel";
				reg = <0x80 0x80>;
				interrupts = <465 2 0 0>;
			};
			dma-channel@100 {
				compatible = "fsl,eloplus-dma-channel";
				reg = <0x100 0x80>;
				interrupts = <466 2 0 0>;
			};
			dma-channel@180 {
				compatible = "fsl,eloplus-dma-channel";
				reg = <0x180 0x80>;
				interrupts = <467 2 0 0>;
			};
			dma-channel@300 {
				compatible = "fsl,eloplus-dma-channel";
				reg = <0x300 0x80>;
				interrupts = <468 2 0 0>;
			};
			dma-channel@380 {
				compatible = "fsl,eloplus-dma-channel";
				reg = <0x380 0x80>;
				interrupts = <469 2 0 0>;
			};
			dma-channel@400 {
				compatible = "fsl,eloplus-dma-channel";
				reg = <0x400 0x80>;
				interrupts = <470 2 0 0>;
			};
			dma-channel@480 {
				compatible = "fsl,eloplus-dma-channel";
				reg = <0x480 0x80>;
				interrupts = <471 2 0 0>;
			};
		};

		i2c0: i2c@118000 {
			compatible = "fsl-i2c";
			#address-cells = <1>;
			#size-cells = <0>;
			cell-index = <0>;
			reg = <0x118000 0x100>;
			interrupts = <38 2 0 0>;
			dfsrr;
		};

		i2c1: i2c@118100 {
			compatible = "fsl-i2c";
			#address-cells = <1>;
			#size-cells = <0>;
			cell-index = <1>;
			reg = <0x118100 0x100>;
			interrupts = <38 2 0 0>;
			dfsrr;
		};

		i2c2: i2c@119000 {
			#address-cells = <1>;
			#size-cells = <0>;
			cell-index = <2>;
			compatible = "fsl-i2c";
			reg = <0x119000 0x100>;
			interrupts = <39 2 0 0>;
			dfsrr;
		};

		i2c3: i2c@119100 {
			#address-cells = <1>;
			#size-cells = <0>;
			cell-index = <3>;
			compatible = "fsl-i2c";
			reg = <0x119100 0x100>;
			interrupts = <39 2 0 0>;
			dfsrr;
		};

		serial0: serial@11c500 {
			compatible = "fsl,ns16550", "ns16550";
			device_type = "serial";
			cell-index = <0>;
			reg = <0x11c500 0x100>;
			clock-frequency = <300000000>;
			interrupts = <36 2 0 0>;
		};

		serial1: serial@11c600 {
			compatible = "fsl,ns16550", "ns16550";
			device_type = "serial";
			cell-index = <1>;
			reg = <0x11c600 0x100>;
			clock-frequency = <300000000>;
			interrupts = <36 2 0 0>;
		};

		serial2: serial@11d500 {
			compatible = "fsl,ns16550", "ns16550";
			device_type = "serial";
			cell-index = <2>;
			reg = <0x11d500 0x100>;
			clock-frequency = <300000000>;
			interrupts = <37 2 0 0>;
		};

		serial3: serial@11d600 {
			compatible = "fsl,ns16550", "ns16550";
			device_type = "serial";
			cell-index = <3>;
			reg = <0x11d600 0x100>;
			clock-frequency = <300000000>;
			interrupts = <37 2 0 0>;
		};

		gpio@130000 {
			compatible = "fsl,qoriq-gpio";
			reg = <0x130000 0x1000>;
			interrupts = <55 2 0 0>;
			#gpio-cells = <2>;
			gpio-controller;
		};

		gpio@131000 {
			compatible = "fsl,qoriq-gpio";
			reg = <0x131000 0x1000>;
			interrupts = <54 2 0 0>;
			#gpio-cells = <2>;
			gpio-controller;
		};

		gpio@132000 {
			compatible = "fsl,qoriq-gpio";
			reg = <0x132000 0x1000>;
			interrupts = <86 2 0 0>;
			#gpio-cells = <2>;
			gpio-controller;
		};

		gpio@133000 {
			compatible = "fsl,qoriq-gpio";
			reg = <0x133000 0x1000>;
			interrupts = <87 2 0 0>;
			#gpio-cells = <2>;
			gpio-controller;
		};

		rman: rman@1e0000 {
			compatible = "fsl,rman";
			#address-cells = <1>;
			#size-cells = <1>;
			ranges = <0x0 0x1e0000 0x20000>;
			reg = <0x1e0000 0x20000>;
			interrupts = <16 2 1 11>; /* err_irq */

			inbound-block@0 {
				compatible = "fsl,rman-inbound-block";
				reg = <0x0 0x800>;
			};

			global-cfg@b00 {
				compatible = "fsl,rman-global-cfg";
				reg = <0xb00 0x500>;
			};

			inbound-block@1000 {
				compatible = "fsl,rman-inbound-block";
				reg = <0x1000 0x800>;
			};

			inbound-block@2000 {
				compatible = "fsl,rman-inbound-block";
				reg = <0x2000 0x800>;
			};

			inbound-block@3000 {
				compatible = "fsl,rman-inbound-block";
				reg = <0x3000 0x800>;
			};
		};

		usb0: usb@210000 {
			compatible = "fsl-usb2-mph-v2.5", "fsl-usb2-mph";
			#address-cells = <1>;
			#size-cells = <0>;
			reg = <0x210000 0x1000>;
			interrupts = <44 2 0 0>;
			fsl,iommu-parent = <&pamu1>;
			dr_mode = "host";
			phy_type = "utmi";
			port0;
			fsl,usb-erratum-a007792;
			status = "disabled";
		};

		usb1: usb@211000 {
			compatible = "fsl-usb2-dr-v2.5", "fsl-usb2-dr";
			#address-cells = <1>;
			#size-cells = <0>;
			reg = <0x211000 0x1000>;
			interrupts = <45 2 0 0>;
			fsl,iommu-parent = <&pamu1>;
			dr_mode = "host";
			phy_type = "utmi";
			fsl,usb-erratum-a007792;
			status = "disabled";
		};

		sata@220000 {
			compatible = "fsl,pq-sata-v2";
			reg = <0x220000 0x1000>;
			interrupts = <68 2 0 0>;
			fsl,iommu-parent = <&pamu1>;
		};

		sata@221000 {
			compatible = "fsl,pq-sata-v2";
			reg = <0x221000 0x1000>;
			interrupts = <69 2 0 0>;
			fsl,iommu-parent = <&pamu1>;
		};

/*
		crypto: crypto@300000 {
			compatible = "fsl,sec-v5.2", "fsl,sec-v5.0", "fsl,sec-v4.0";
			fsl,sec-era = <5>;
			#address-cells = <1>;
			#size-cells = <1>;
			reg = <0x300000 0x10000>;
			ranges = <0x0 0x300000 0x10000>;
			interrupts = <92 2 0 0>;

			sec_jr0: jr@1000 {
				compatible = "fsl,sec-v5.2-job-ring",
				             "fsl,sec-v5.0-job-ring",
				             "fsl,sec-v4.0-job-ring";
				reg = <0x1000 0x1000>;
				interrupts = <88 2 0 0>;
			};

			sec_jr1: jr@2000 {
				compatible = "fsl,sec-v5.2-job-ring",
				             "fsl,sec-v5.0-job-ring",
				             "fsl,sec-v4.0-job-ring";
				reg = <0x2000 0x1000>;
				interrupts = <89 2 0 0>;
			};

			sec_jr2: jr@3000 {
				compatible = "fsl,sec-v5.2-job-ring",
				             "fsl,sec-v5.0-job-ring",
				             "fsl,sec-v4.0-job-ring";
				reg = <0x3000 0x1000>;
				interrupts = <90 2 0 0>;
			};

			sec_jr3: jr@4000 {
				compatible = "fsl,sec-v5.2-job-ring",
				             "fsl,sec-v5.0-job-ring",
				             "fsl,sec-v4.0-job-ring";
				reg = <0x4000 0x1000>;
				interrupts = <91 2 0 0>;
			};

			rtic@6000 {
				compatible = "fsl,sec-v5.2-rtic",
				             "fsl,sec-v5.0-rtic",
				             "fsl,sec-v4.0-rtic";
				#address-cells = <1>;
				#size-cells = <1>;
				reg = <0x6000 0x100>;
				ranges = <0x0 0x6100 0xe00>;

				rtic_a: rtic-a@0 {
					compatible = "fsl,sec-v5.2-rtic-memory",
					             "fsl,sec-v5.0-rtic-memory",
					             "fsl,sec-v4.0-rtic-memory";
					reg = <0x00 0x20 0x100 0x80>;
				};

				rtic_b: rtic-b@20 {
					compatible = "fsl,sec-v5.2-rtic-memory",
					             "fsl,sec-v5.0-rtic-memory",
					             "fsl,sec-v4.0-rtic-memory";
					reg = <0x20 0x20 0x200 0x80>;
				};

				rtic_c: rtic-c@40 {
					compatible = "fsl,sec-v5.2-rtic-memory",
					             "fsl,sec-v5.0-rtic-memory",
					             "fsl,sec-v4.0-rtic-memory";
					reg = <0x40 0x20 0x300 0x80>;
				};

				rtic_d: rtic-d@60 {
					compatible = "fsl,sec-v5.2-rtic-memory",
					             "fsl,sec-v5.0-rtic-memory",
					             "fsl,sec-v4.0-rtic-memory";
					reg = <0x60 0x20 0x500 0x80>;
				};
			};
		};
*/
		sec_mon: sec_mon@314000 {
			compatible = "fsl,sec-v5.2-mon",
			             "fsl,sec-v5.0-mon",
			             "fsl,sec-v4.0-mon";
			reg = <0x314000 0x1000>;
			interrupts = <93 2 0 0>;
		};

		dce: dce@312000 {
			compatible = "fsl,dce";
			reg = <0x312000 0x10000>;
			interrupts = <16 2 1 4>;
		};

		pme: pme@316000 {
			compatible = "fsl,pme";
			reg = <0x316000 0x10000>;
			interrupts = <16 2 1 5>;
		};

		qman: qman@318000 {
			compatible = "fsl,qman";
			/* QMan rev3 has 8KB CCSR space */
			reg = <0x318000 0x2000>;
			interrupts = <16 2 1 3>;
		};

		bman: bman@31a000 {
			compatible = "fsl,bman";
			reg = <0x31a000 0x1000>;
			interrupts = <16 2 1 2>;
		};

		l2: l2-cache-controller@c20000 {
			/* Cluster 0 L2 cache */
			compatible = "fsl,t2080-l2-cache-controller";
			reg = <0xc20000 0x40000>;
			next-level-cache = <&cpc>;
		};
	};

	rio: rapidio@ffe0c0000 {
		compatible = "fsl,srio";
		reg = <0xf 0xfe0c0000 0 0x11000>;
		#address-cells = <2>;
		#size-cells = <2>;
		interrupts = <16 2 1 11>;
		fsl,iommu-parent = <&pamu0>;
		fsl,srio-rmu-handle = <&srio>;
		ranges;
		status = "disabled";

		port1 {
			#address-cells = <2>;
			#size-cells = <2>;
			cell-index = <1>;
			ranges = <0 0 0xc 0x20000000 0 0x10000000>;
		};

		port2 {
			#address-cells = <2>;
			#size-cells = <2>;
			cell-index = <2>;
			ranges = <0 0 0xc 0x30000000 0 0x10000000>;
		};
	};

/*
	pci:
		ranges = <'phys.hi' 'phys.mid' 'phys.low'
		          'parent.hi' 'parent.lo'
		          'size.hi' 'size.lo'>
		dma-ranges = [same as ranges]

		phys.hi  cell: npt000ss bbbbbbbb dddddfff rrrrrrrr
		phys.mid cell: hhhhhhhh hhhhhhhh hhhhhhhh hhhhhhhh
		phys.low cell: llllllll llllllll llllllll llllllll

		flags:
			- n:  relocatable region
			- p:  prefetchable (cacheable) region flag
			- t:  aliased address flag
			- ss: space code
				'00' configuration space
				'01' I/O space
				'10' 32 bit memory space
				'11' 64 bit memory space
			- bbbbbbbb: PCI bus number
			- ddddd: PCI device number
			- fff: PCI function number
			- rrrrrrrr: PCI register number


		interrupt-map:
			interrupt-map = <'child.hi' 'child.mid' 'child.low' 'child-int'
			                 'parent-handle'
			                 'parent.high' 'parent.low'
			                 'parent-interrupt'>
*/

	pcie@ffe240000 {
		compatible = "pcie", "fsl,t2080-pcie", "fsl,qoriq-pcie-v3.0", "fsl,qoriq-pcie";
		device_type = "pci";
		#size-cells = <2>;
		#address-cells = <3>;
		bus-range = <0 255>;
		interrupts = <20 2 0 0>;
		fsl,msi = <&msi0>;
		fsl,iommu-parent = <&pamu0>;
		reg = <0xf 0xfe240000 0 0x10000>;
	};

	pcie@ffe250000 {
		compatible = "fsl,t2080-pcie", "fsl,qoriq-pcie-v3.0", "fsl,qoriq-pcie";
		device_type = "pci";
		#size-cells = <2>;
		#address-cells = <3>;
		bus-range = <0 255>;
		interrupts = <21 2 0 0>;
		fsl,msi = <&msi1>;
		fsl,iommu-parent = <&pamu0>;
		reg = <0xf 0xfe250000 0 0x10000>;
		status = "disabled";
	};

	pcie@ffe260000 {
		compatible = "fsl,t2080-pcie", "fsl,qoriq-pcie-v3.0", "fsl,qoriq-pcie";
		device_type = "pci";
		#size-cells = <2>;
		#address-cells = <3>;
		bus-range = <0 255>;
		interrupts = <22 2 0 0>;
		fsl,msi = <&msi2>;
		fsl,iommu-parent = <&pamu0>;
		reg = <0xf 0xfe260000 0 0x10000>;
		status = "disabled";
	};

	pcie@ffe270000 {
		compatible = "fsl,t2080-pcie", "fsl,qoriq-pcie-v3.0", "fsl,qoriq-pcie";
		device_type = "pci";
		#size-cells = <2>;
		#address-cells = <3>;
		bus-range = <0 255>;
		interrupts = <23 2 0 0>;
		fsl,msi = <&msi3>;
		fsl,iommu-parent = <&pamu0>;
		reg = <0xf 0xfe270000 0 0x10000>;
		status = "disabled";
	};

	fsl,dpaa {
		compatible = "fsl,t2080-dpaa", "fsl,dpaa";
		ethernet@0 {
			compatible = "fsl,dpa-ethernet";
			fsl,fman-mac = <&fm1mac1>;
			status = "disabled";
		};
		ethernet@1 {
			compatible = "fsl,dpa-ethernet";
			fsl,fman-mac = <&fm1mac2>;
			status = "disabled";
		};
		ethernet@2 {
			compatible = "fsl,dpa-ethernet";
			fsl,fman-mac = <&fm1mac3>;
			status = "disabled";
		};
	};
};

/include/ "mfcc_855x_liodn.dtsi"
